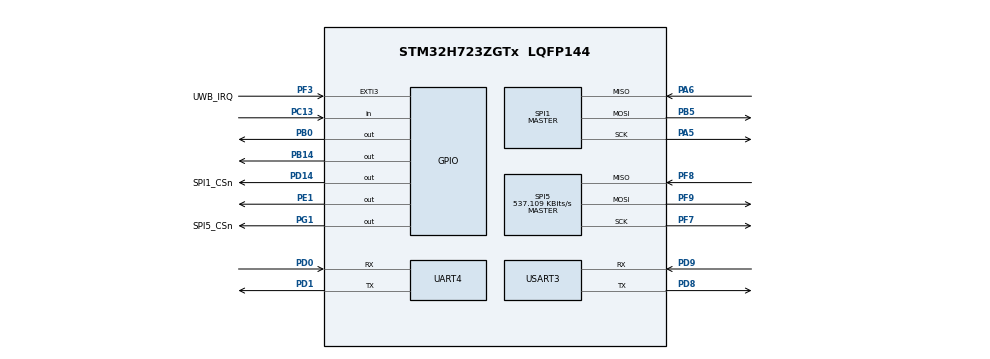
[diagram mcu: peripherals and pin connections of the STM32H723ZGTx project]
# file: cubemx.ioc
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ARM.CMSIS-DSP.1.17.0.CMSISJjDSP=Source
CORTEX_M7.default_mode_Activation=1
Dma.Request0=UART4_RX
Dma.Request1=USART3_RX
Dma.Request2=USART3_TX
Dma.Request3=UART4_TX
Dma.UART4_RX.0.Direction=DMA_PERIPH_TO_MEMORY
Dma.UART4_RX.0.EventEnable=DISABLE
Dma.UART4_RX.0.FIFOMode=DMA_FIFOMODE_DISABLE
Dma.UART4_RX.0.Instance=DMA1_Stream0
Dma.UART4_RX.0.MemDataAlignment=DMA_MDATAALIGN_BYTE
Dma.UART4_RX.0.MemInc=DMA_MINC_ENABLE
Dma.UART4_RX.0.Mode=DMA_CIRCULAR
Dma.UART4_RX.0.PeriphDataAlignment=DMA_PDATAALIGN_BYTE
Dma.UART4_RX.0.PeriphInc=DMA_PINC_DISABLE
Dma.UART4_RX.0.Polarity=HAL_DMAMUX_REQ_GEN_RISING
Dma.UART4_RX.0.Priority=DMA_PRIORITY_LOW
Dma.UART4_RX.0.RequestNumber=1
Dma.UART4_RX.0.SignalID=NONE
Dma.UART4_RX.0.SyncEnable=DISABLE
Dma.UART4_RX.0.SyncPolarity=HAL_DMAMUX_SYNC_NO_EVENT
Dma.UART4_RX.0.SyncRequestNumber=1
Dma.UART4_RX.0.SyncSignalID=NONE
Dma.UART4_TX.3.Direction=DMA_MEMORY_TO_PERIPH
Dma.UART4_TX.3.EventEnable=DISABLE
Dma.UART4_TX.3.FIFOMode=DMA_FIFOMODE_DISABLE
Dma.UART4_TX.3.Instance=DMA1_Stream3
Dma.UART4_TX.3.MemDataAlignment=DMA_MDATAALIGN_BYTE
Dma.UART4_TX.3.MemInc=DMA_MINC_ENABLE
Dma.UART4_TX.3.Mode=DMA_NORMAL
Dma.UART4_TX.3.PeriphDataAlignment=DMA_PDATAALIGN_BYTE
Dma.UART4_TX.3.PeriphInc=DMA_PINC_DISABLE
Dma.UART4_TX.3.Polarity=HAL_DMAMUX_REQ_GEN_RISING
Dma.UART4_TX.3.Priority=DMA_PRIORITY_LOW
Dma.UART4_TX.3.RequestNumber=1
Dma.UART4_TX.3.SignalID=NONE
Dma.UART4_TX.3.SyncEnable=DISABLE
Dma.UART4_TX.3.SyncPolarity=HAL_DMAMUX_SYNC_NO_EVENT
Dma.UART4_TX.3.SyncRequestNumber=1
Dma.UART4_TX.3.SyncSignalID=NONE
Dma.USART3_RX.1.Direction=DMA_PERIPH_TO_MEMORY
Dma.USART3_RX.1.EventEnable=DISABLE
Dma.USART3_RX.1.FIFOMode=DMA_FIFOMODE_DISABLE
Dma.USART3_RX.1.Instance=DMA1_Stream1
Dma.USART3_RX.1.MemDataAlignment=DMA_MDATAALIGN_BYTE
Dma.USART3_RX.1.MemInc=DMA_MINC_ENABLE
Dma.USART3_RX.1.Mode=DMA_CIRCULAR
Dma.USART3_RX.1.PeriphDataAlignment=DMA_PDATAALIGN_BYTE
Dma.USART3_RX.1.PeriphInc=DMA_PINC_DISABLE
Dma.USART3_RX.1.Polarity=HAL_DMAMUX_REQ_GEN_RISING
Dma.USART3_RX.1.Priority=DMA_PRIORITY_LOW
Dma.USART3_RX.1.RequestNumber=1
Dma.USART3_RX.1.SignalID=NONE
Dma.USART3_RX.1.SyncEnable=DISABLE
Dma.USART3_RX.1.SyncPolarity=HAL_DMAMUX_SYNC_NO_EVENT
Dma.USART3_RX.1.SyncRequestNumber=1
Dma.USART3_RX.1.SyncSignalID=NONE
Dma.USART3_TX.2.Direction=DMA_MEMORY_TO_PERIPH
Dma.USART3_TX.2.EventEnable=DISABLE
Dma.USART3_TX.2.FIFOMode=DMA_FIFOMODE_DISABLE
Dma.USART3_TX.2.Instance=DMA1_Stream2
Dma.USART3_TX.2.MemDataAlignment=DMA_MDATAALIGN_BYTE
Dma.USART3_TX.2.MemInc=DMA_MINC_ENABLE
Dma.USART3_TX.2.Mode=DMA_NORMAL
Dma.USART3_TX.2.PeriphDataAlignment=DMA_PDATAALIGN_BYTE
Dma.USART3_TX.2.PeriphInc=DMA_PINC_DISABLE
Dma.USART3_TX.2.Polarity=HAL_DMAMUX_REQ_GEN_RISING
Dma.USART3_TX.2.Priority=DMA_PRIORITY_LOW
Dma.USART3_TX.2.RequestNumber=1
Dma.USART3_TX.2.SignalID=NONE
Dma.USART3_TX.2.SyncEnable=DISABLE
Dma.USART3_TX.2.SyncPolarity=HAL_DMAMUX_SYNC_NO_EVENT
Dma.USART3_TX.2.SyncRequestNumber=1
Dma.USART3_TX.2.SyncSignalID=NONE
FREERTOS.INCLUDE_xTaskGetHandle=1
FREERTOS.Tasks01=defaultTask,24,512,StartDefaultTask,Default,NULL,Dynamic,NULL,NULL
FREERTOS.configENABLE_FPU=1
FREERTOS.configGENERATE_RUN_TIME_STATS=1
FREERTOS.configMAX_TASK_NAME_LEN=32
FREERTOS.configTOTAL_HEAP_SIZE=65536
FREERTOS.configUSE_STATS_FORMATTING_FUNCTIONS=1
IWDG1.Prescaler=IWDG_PRESCALER_64
Mcu.Family=STM32H7
Mcu.Name=STM32H723ZGTx
Mcu.Package=LQFP144
NUCLEO-H723ZG.BUTTON=1
NUCLEO-H723ZG.LD1=true
NUCLEO-H723ZG.LD2=true
NUCLEO-H723ZG.LD3=true
NUCLEO-H723ZG.VCP=false
NVIC.DMA1_Stream0_IRQn=true\:5\:0\:false\:false\:true\:true\:false\:true\:true
NVIC.DMA1_Stream1_IRQn=true\:5\:0\:false\:false\:true\:true\:false\:true\:true
NVIC.DMA1_Stream2_IRQn=true\:5\:0\:false\:false\:true\:true\:false\:true\:true
NVIC.DMA1_Stream3_IRQn=true\:5\:0\:false\:false\:true\:true\:false\:true\:true
NVIC.EXTI15_10_IRQn=true\:5\:0\:false\:false\:true\:true\:false\:true\:true
NVIC.EXTI3_IRQn=true\:5\:0\:false\:false\:true\:true\:true\:true\:true
NVIC.PriorityGroup=NVIC_PRIORITYGROUP_4
NVIC.TIM6_DAC_IRQn=true\:0\:0\:true\:false\:true\:false\:false\:true\:true
NVIC.TimeBase=TIM6_DAC_IRQn
NVIC.TimeBaseIP=TIM6
NVIC.UART4_IRQn=true\:5\:0\:false\:false\:true\:true\:true\:true\:true
NVIC.USART3_IRQn=true\:5\:0\:false\:false\:true\:true\:true\:true\:true
PA13(JTMS/SWDIO).GPIO_Label=SWDIO
PA13(JTMS/SWDIO).Mode=Serial_Wire
PA13(JTMS/SWDIO).Signal=DEBUG_JTMS-SWDIO
PA14(JTCK/SWCLK).GPIO_Label=SWCLK
PA14(JTCK/SWCLK).Mode=Serial_Wire
PA14(JTCK/SWCLK).Signal=DEBUG_JTCK-SWCLK
PA5.Mode=Full_Duplex_Master
PA5.Signal=SPI1_SCK
PA6.Mode=Full_Duplex_Master
PA6.Signal=SPI1_MISO
PB0.Signal=GPIO_Output
PB14.Signal=GPIO_Output
PB5.Mode=Full_Duplex_Master
PB5.Signal=SPI1_MOSI
PC13.Signal=GPIO_Input
PC14-OSC32_IN.Signal=RCC_OSC32_IN
PC15-OSC32_OUT.Signal=RCC_OSC32_OUT
PD0.Mode=Asynchronous
PD0.Signal=UART4_RX
PD1.Mode=Asynchronous
PD1.Signal=UART4_TX
PD14.GPIO_Label=SPI1_CSn
PD14.Signal=GPIO_Output
PD8.Mode=Asynchronous
PD8.Signal=USART3_TX
PD9.Mode=Asynchronous
PD9.Signal=USART3_RX
PE1.Signal=GPIO_Output
PF3.GPIO_Label=UWB_IRQ
PF3.GPIO_PuPd=GPIO_PULLDOWN
PF3.Signal=GPXTI3
PF7.Mode=Full_Duplex_Master
PF7.Signal=SPI5_SCK
PF8.Mode=Full_Duplex_Master
PF8.Signal=SPI5_MISO
PF9.Mode=Full_Duplex_Master
PF9.Signal=SPI5_MOSI
PG1.GPIO_Label=SPI5_CSn
PG1.PinState=GPIO_PIN_SET
PG1.Signal=GPIO_Output
ProjectManager.HeapSize=0x200
ProjectManager.StackSize=0x400
ProjectManager.TargetToolchain=CMake
RCC.ADCFreq_Value=608000000
RCC.APB1Freq_Value=137500000
RCC.APB2Freq_Value=137500000
RCC.APB3Freq_Value=137500000
RCC.APB4Freq_Value=137500000
RCC.CortexFreq_Value=550000000
RCC.D1PPRE=RCC_APB3_DIV2
RCC.D2PPRE1=RCC_APB1_DIV2
RCC.D2PPRE2=RCC_APB2_DIV2
RCC.D3PPRE=RCC_APB4_DIV2
RCC.DIVM1=4
RCC.DIVM2=1
RCC.DIVN1=34
RCC.DIVN2=19
RCC.DIVP1=1
RCC.DIVQ1=3
RCC.HCLKFreq_Value=275000000
RCC.HPRE=RCC_HCLK_DIV2
RCC.HSE_VALUE=8000000
RCC.PLLFRACN=3072
RCC.SYSCLKFreq_VALUE=550000000
RCC.SYSCLKSource=RCC_SYSCLKSOURCE_PLLCLK
RCC.USBCLockSelection=RCC_USBCLKSOURCE_HSI48
RCC.USBFreq_Value=48000000
SPI1.BaudRatePrescaler=SPI_BAUDRATEPRESCALER_16
SPI1.CalculateBaudRate=11.458333 MBits/s
SPI1.DataSize=SPI_DATASIZE_8BIT
SPI1.Direction=SPI_DIRECTION_2LINES
SPI1.Mode=SPI_MODE_MASTER
SPI1.NSSPMode=SPI_NSS_PULSE_DISABLE
SPI1.VirtualType=VM_MASTER
SPI5.BaudRatePrescaler=SPI_BAUDRATEPRESCALER_256
SPI5.CLKPhase=SPI_PHASE_1EDGE
SPI5.CLKPolarity=SPI_POLARITY_LOW
SPI5.CalculateBaudRate=537.109 KBits/s
SPI5.DataSize=SPI_DATASIZE_8BIT
SPI5.Direction=SPI_DIRECTION_2LINES
SPI5.Mode=SPI_MODE_MASTER
SPI5.VirtualType=VM_MASTER
TIM5.Prescaler=27
USART3.VirtualMode-Asynchronous=VM_ASYNC
VP_ARM.CMSIS-DSP_VS_CMSISJjDSP_1.17.0_1.17.0.Mode=CMSISJjDSP
VP_FREERTOS_VS_CMSIS_V2.Mode=CMSIS_V2
VP_IWDG1_VS_IWDG.Mode=IWDG_Activate
VP_MEMORYMAP_VS_MEMORYMAP.Mode=CurAppReg
VP_NUCLEO-H723ZG_VS_BSP_COMMON.Mode=COMMON
VP_SYS_VS_tim6.Mode=TIM6
VP_TIM5_VS_ClockSourceINT.Mode=Internal
board=NUCLEO-H723ZG

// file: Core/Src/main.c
/* USER CODE BEGIN Header */
/**
  ******************************************************************************
  * @file           : main.c
  * @brief          : Main program body
  ******************************************************************************
  * @attention
  *
  * Copyright (c) 2025 STMicroelectronics.
  * All rights reserved.
  *
  * This software is licensed under terms that can be found in the LICENSE file
  * in the root directory of this software component.
  * If no LICENSE file comes with this software, it is provided AS-IS.
  *
  ******************************************************************************
  */
/* USER CODE END Header */
#include "main.h"
#include "cmsis_os.h"
#include "dma.h"
#include "iwdg.h"
#include "spi.h"
#include "tim.h"
#include "usart.h"
#include "gpio.h"

/* USER CODE BEGIN Includes */

#include "app.h"
#include "platform_os.h"
#include "platform_timer.h"

/* USER CODE END Includes */

void SystemClock_Config(void);
static void MPU_Config(void);
void MX_FREERTOS_Init(void);

int main(void)
{

  /* MPU Configuration--------------------------------------------------------*/
  MPU_Config();

  /* MCU Configuration--------------------------------------------------------*/

  /* Reset of all peripherals, Initializes the Flash interface and the Systick. */
  HAL_Init();

  /* Configure the system clock */
  SystemClock_Config();

  /* USER CODE BEGIN SysInit */

  /* Initialize platform OS layer (DWT, etc.) */
  platform_os_init();

  /* USER CODE END SysInit */

  /* Initialize all configured peripherals */
  MX_GPIO_Init();
  MX_DMA_Init();
  MX_TIM5_Init();
  MX_SPI1_Init();
  MX_SPI5_Init();
  MX_UART4_Init();
  MX_USART3_UART_Init();
  MX_IWDG1_Init();
  /* USER CODE BEGIN 2 */

  // NOTE: IWDG starts here (~8s timeout). Watchdog module will refresh it after RTOS starts.

  /* USER CODE END 2 */

  /* Init scheduler */
  osKernelInitialize();  /* Call init function for freertos objects (in cmsis_os2.c) */
  MX_FREERTOS_Init();

  /* Initialize leds */
  BSP_LED_Init(LED_GREEN);
  BSP_LED_Init(LED_YELLOW);
  BSP_LED_Init(LED_RED);

  /* Initialize USER push-button, will be used to trigger an interrupt each time it's pressed.*/
  BSP_PB_Init(BUTTON_USER, BUTTON_MODE_EXTI);

  /* Start scheduler */
  osKernelStart();

  /* We should never get here as control is now taken by the scheduler */

  /* Infinite loop */
  while (1)
  {

  }
}

void SystemClock_Config(void)
{
  RCC_OscInitTypeDef RCC_OscInitStruct = {0};
  RCC_ClkInitTypeDef RCC_ClkInitStruct = {0};

  /** Supply configuration update enable
  */
  HAL_PWREx_ConfigSupply(PWR_LDO_SUPPLY);

  /** Configure the main internal regulator output voltage
  */
  __HAL_PWR_VOLTAGESCALING_CONFIG(PWR_REGULATOR_VOLTAGE_SCALE0);

  while(!__HAL_PWR_GET_FLAG(PWR_FLAG_VOSRDY)) {}

  /** Initializes the RCC Oscillators according to the specified parameters
  * in the RCC_OscInitTypeDef structure.
  */
  RCC_OscInitStruct.OscillatorType = RCC_OSCILLATORTYPE_HSI|RCC_OSCILLATORTYPE_LSI;
  RCC_OscInitStruct.HSIState = RCC_HSI_DIV1;
  RCC_OscInitStruct.HSICalibrationValue = 64;
  RCC_OscInitStruct.LSIState = RCC_LSI_ON;
  RCC_OscInitStruct.PLL.PLLState = RCC_PLL_ON;
  RCC_OscInitStruct.PLL.PLLSource = RCC_PLLSOURCE_HSI;
  RCC_OscInitStruct.PLL.PLLM = 4;
  RCC_OscInitStruct.PLL.PLLN = 34;
  RCC_OscInitStruct.PLL.PLLP = 1;
  RCC_OscInitStruct.PLL.PLLQ = 3;
  RCC_OscInitStruct.PLL.PLLR = 2;
  RCC_OscInitStruct.PLL.PLLRGE = RCC_PLL1VCIRANGE_3;
  RCC_OscInitStruct.PLL.PLLVCOSEL = RCC_PLL1VCOWIDE;
  RCC_OscInitStruct.PLL.PLLFRACN = 3072;
  if (HAL_RCC_OscConfig(&RCC_OscInitStruct) != HAL_OK)
  {
    Error_Handler();
  }

  /** Initializes the CPU, AHB and APB buses clocks
  */
  RCC_ClkInitStruct.ClockType = RCC_CLOCKTYPE_HCLK|RCC_CLOCKTYPE_SYSCLK
                              |RCC_CLOCKTYPE_PCLK1|RCC_CLOCKTYPE_PCLK2
                              |RCC_CLOCKTYPE_D3PCLK1|RCC_CLOCKTYPE_D1PCLK1;
  RCC_ClkInitStruct.SYSCLKSource = RCC_SYSCLKSOURCE_PLLCLK;
  RCC_ClkInitStruct.SYSCLKDivider = RCC_SYSCLK_DIV1;
  RCC_ClkInitStruct.AHBCLKDivider = RCC_HCLK_DIV2;
  RCC_ClkInitStruct.APB3CLKDivider = RCC_APB3_DIV2;
  RCC_ClkInitStruct.APB1CLKDivider = RCC_APB1_DIV2;
  RCC_ClkInitStruct.APB2CLKDivider = RCC_APB2_DIV2;
  RCC_ClkInitStruct.APB4CLKDivider = RCC_APB4_DIV2;

  if (HAL_RCC_ClockConfig(&RCC_ClkInitStruct, FLASH_LATENCY_3) != HAL_OK)
  {
    Error_Handler();
  }
}

 /* MPU Configuration */

void MPU_Config(void)
{
  MPU_Region_InitTypeDef MPU_InitStruct = {0};

  /* Disables the MPU */
  HAL_MPU_Disable();

  /** Initializes and configures the Region and the memory to be protected
  */
  MPU_InitStruct.Enable = MPU_REGION_ENABLE;
  MPU_InitStruct.Number = MPU_REGION_NUMBER0;
  MPU_InitStruct.BaseAddress = 0x0;
  MPU_InitStruct.Size = MPU_REGION_SIZE_4GB;
  MPU_InitStruct.SubRegionDisable = 0x87;
  MPU_InitStruct.TypeExtField = MPU_TEX_LEVEL0;
  MPU_InitStruct.AccessPermission = MPU_REGION_NO_ACCESS;
  MPU_InitStruct.DisableExec = MPU_INSTRUCTION_ACCESS_DISABLE;
  MPU_InitStruct.IsShareable = MPU_ACCESS_SHAREABLE;
  MPU_InitStruct.IsCacheable = MPU_ACCESS_NOT_CACHEABLE;
  MPU_InitStruct.IsBufferable = MPU_ACCESS_NOT_BUFFERABLE;

  HAL_MPU_ConfigRegion(&MPU_InitStruct);
  /* Enables the MPU */
  HAL_MPU_Enable(MPU_PRIVILEGED_DEFAULT);

}

void HAL_TIM_PeriodElapsedCallback(TIM_HandleTypeDef *htim)
{
  if (htim->Instance == TIM6)
  {
    HAL_IncTick();
  }
}

void Error_Handler(void)
{
  __disable_irq();
  while (1)
  {
  }
}

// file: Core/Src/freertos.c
/* USER CODE BEGIN Header */
/**
  ******************************************************************************
  * File Name          : freertos.c
  * Description        : Code for freertos applications
  ******************************************************************************
  * @attention
  *
  * Copyright (c) 2025 STMicroelectronics.
  * All rights reserved.
  *
  * This software is licensed under terms that can be found in the LICENSE file
  * in the root directory of this software component.
  * If no LICENSE file comes with this software, it is provided AS-IS.
  *
  ******************************************************************************
  */
/* USER CODE END Header */

#include "FreeRTOS.h"
#include "task.h"
#include "main.h"
#include "cmsis_os.h"

/* USER CODE BEGIN Includes */
#include "app.h"
#include "tim.h"
/* USER CODE END Includes */

/* Definitions for defaultTask */
osThreadId_t defaultTaskHandle;
const osThreadAttr_t defaultTask_attributes = {
  .name = "defaultTask",
  .stack_size = 512 * 4,
  .priority = (osPriority_t) osPriorityNormal,
};

void StartDefaultTask(void *argument);

void MX_FREERTOS_Init(void); /* (MISRA C 2004 rule 8.1) */

/* Hook prototypes */
void configureTimerForRunTimeStats(void);
unsigned long getRunTimeCounterValue(void);

/* USER CODE BEGIN 1 */
/* Functions needed when configGENERATE_RUN_TIME_STATS is on */
void configureTimerForRunTimeStats(void) {
    HAL_TIM_Base_Start(&htim5);
}

unsigned long getRunTimeCounterValue(void) {
    return TIM5->CNT;
}

/* Stack overflow hook */
void vApplicationStackOverflowHook(TaskHandle_t xTask, char *pcTaskName)
{
    /* This function will be called if a stack overflow is detected */
    /* Halt execution for debugging */
    (void)xTask;
    (void)pcTaskName;
    taskDISABLE_INTERRUPTS();
    for(;;);
}
/* USER CODE END 1 */

void MX_FREERTOS_Init(void) {

  /* Create the thread(s) */
  /* creation of defaultTask */
  defaultTaskHandle = osThreadNew(StartDefaultTask, NULL, &defaultTask_attributes);

}

void StartDefaultTask(void *argument)
{
  /* USER CODE BEGIN StartDefaultTask */
  /* Infinite loop */
  (void)(argument);
  app_init();
  /* USER CODE END StartDefaultTask */
}
